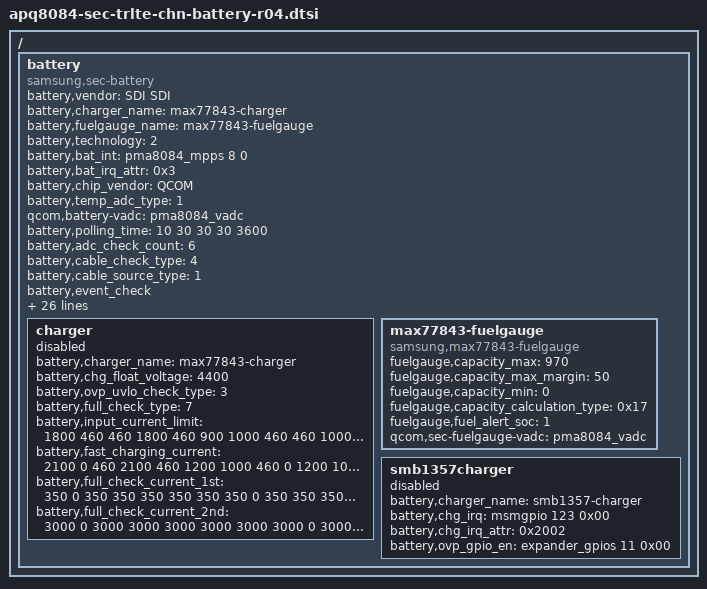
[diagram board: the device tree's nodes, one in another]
/* Copyright (c) 2012, The Linux Foundation. All rights reserved.
 *
 * This program is free software; you can redistribute it and/or modify
 * it under the terms of the GNU General Public License version 2 and
 * only version 2 as published by the Free Software Foundation.
 *
 * This program is distributed in the hope that it will be useful,
 * but WITHOUT ANY WARRANTY; without even the implied warranty of
 * MERCHANTABILITY or FITNESS FOR A PARTICULAR PURPOSE.  See the
 * GNU General Public License for more details.
 */

/ {
	battery {
		status = "okay";
		compatible = "samsung,sec-battery";
		battery,vendor = "SDI SDI";
		battery,charger_name = "max77843-charger";
		battery,fuelgauge_name = "max77843-fuelgauge";
		battery,technology = <2>; /* POWER_SUPPLY_TECHNOLOGY_LION */
		battery,bat_int = <&pma8084_mpps 8 0>;
		battery,bat_irq_attr = <0x3>;

		battery,chip_vendor = "QCOM";
		battery,temp_adc_type = <1>; /* SEC_BATTERY_ADC_TYPE_AP */
		qcom,battery-vadc = <&pma8084_vadc>;

		battery,polling_time = <10 30 30 30 3600>;

		battery,adc_check_count = <6>;

		battery,cable_check_type = <4>; /* SEC_BATTERY_CABLE_CHECK_PSY */
		battery,cable_source_type = <1>; /* SEC_BATTERY_CABLE_SOURCE_EXTERNAL */
		battery,event_check;
		battery,event_waiting_time = <600>;
		battery,polling_type = <1>; /* SEC_BATTERY_MONITOR_ALARM */
		battery,monitor_initial_count = <3>;

		battery,battery_check_type = <6>; /* SEC_BATTERY_CHECK_INT */
		battery,check_count = <0>;
		battery,check_adc_max = <1440>;
		battery,check_adc_min = <0>;

		battery,ovp_uvlo_check_type = <3>; /* SEC_BATTERY_OVP_UVLO_CHGPOLLING */

		battery,thermal_source = <2>; /* SEC_BATTERY_THERMAL_SOURCE_ADC */

		battery,temp_check_type = <2>; /* BATTERY_TEMP_CHECK_TEMP */
		battery,temp_check_count = <1>;
		battery,full_check_type = <7>; /* SEC_BATTERY_FULLCHARGED_CHGPSY */
		battery,full_check_type_2nd = <3>; /* SEC_BATTERY_FULLCHARGED_TIME */
		battery,full_check_count = <1>;
		battery,chg_gpio_full_check = <0>;
		battery,chg_polarity_full_check = <1>;

		/* SEC_BATTERY_FULL_CONDITION_SOC |
		   SEC_BATTERY_FULL_CONDITION_NOTIMEFULL |
		   SEC_BATTERY_FULL_CONDITION_VCELL */
		battery,full_condition_type = <13>;
		battery,full_condition_soc = <93>;
		battery,full_condition_vcell = <4300>;

		battery,recharge_check_count = <1>;
		battery,recharge_condition_type = <4>; /* SEC_BATTERY_RECHARGE_CONDITION_VCELL */
		battery,recharge_condition_soc = <98>;
		battery,recharge_condition_vcell = <4350>;

		battery,charging_total_time = <21600>;
		battery,recharging_total_time = <5400>;
		battery,charging_reset_time = <0>;

		charger {
			status = "disable";
			/* Charger */
			battery,charger_name = "max77843-charger";
			battery,chg_float_voltage = <4400>;
			battery,ovp_uvlo_check_type = <3>; /* SEC_BATTERY_OVP_UVLO_CHGPOLLING */
			battery,full_check_type = <7>; /* SEC_BATTERY_FULLCHARGED_CHGPSY */

			battery,input_current_limit = <1800 460 460 1800 460 900 1000 460 460 1000 820 1800 1800 460 1300 300 700 1300 1500 300 80 900 1500 1000 1000 1667 1667 1667 1400>;
			battery,fast_charging_current = <2100 0 460 2100 460 1200 1000 460 0 1200 1000 2100 2100 0 1300 300 700 1300 1500 300 80 1200 1500 1000 1000 3150 1000 3150 1400>;
			battery,full_check_current_1st = <350 0 350 350 350 350 350 350 0 350 350 350 350 0 350 350 350 350 350 350 350 350 0 350 350 350 350 350 350>;
			battery,full_check_current_2nd = <3000 0 3000 3000 3000 3000 3000 3000 0 3000 3000 3000 3000 0 3000 3000 3000 3000 3000 3000 3000 3000 0 3000 3000 3000 3000 3000 3000>;
		};

		max77843-fuelgauge {
			compatible = "samsung,max77843-fuelgauge";
			fuelgauge,capacity_max = <970>;
			fuelgauge,capacity_max_margin = <50>;
			fuelgauge,capacity_min = <0>;
			fuelgauge,capacity_calculation_type = <0x17>;
			fuelgauge,fuel_alert_soc = <1>;
			/* fuelgaguge,repeated_fuelalert; */
			qcom,sec-fuelgauge-vadc = <&pma8084_vadc>;
		};

		smb1357charger {
			status = "disable";
			battery,charger_name = "smb1357-charger";
			battery,chg_irq = <&msmgpio 123 0x00>;
			battery,chg_irq_attr = <0x2002>; /*IRQF_ONESHOT|IRQ_TRIGGER_FALLING*/
			battery,ovp_gpio_en = <&expander_gpios 11 0x00>;
		};
	};
};
